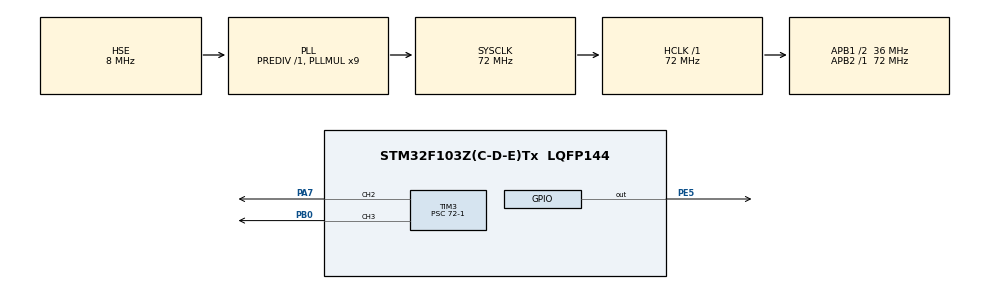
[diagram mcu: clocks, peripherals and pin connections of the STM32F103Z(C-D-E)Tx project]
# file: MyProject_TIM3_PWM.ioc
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Mcu.Family=STM32F1
Mcu.Name=STM32F103Z(C-D-E)Tx
Mcu.Package=LQFP144
NVIC.PriorityGroup=NVIC_PRIORITYGROUP_4
NVIC.TIM3_IRQn=true\:0\:0\:false\:false\:true\:true\:true
OSC_IN.Mode=HSE-External-Oscillator
OSC_IN.Signal=RCC_OSC_IN
OSC_OUT.Mode=HSE-External-Oscillator
OSC_OUT.Signal=RCC_OSC_OUT
PA7.Signal=S_TIM3_CH2
PB0.GPIO_Speed=GPIO_SPEED_FREQ_LOW
PB0.Signal=S_TIM3_CH3
PE5.Signal=GPIO_Output
ProjectManager.HeapSize=0x200
ProjectManager.StackSize=0x400
ProjectManager.TargetToolchain=MDK-ARM V5
RCC.AHBFreq_Value=72000000
RCC.APB1CLKDivider=RCC_HCLK_DIV2
RCC.APB1Freq_Value=36000000
RCC.APB1TimFreq_Value=72000000
RCC.APB2Freq_Value=72000000
RCC.APB2TimFreq_Value=72000000
RCC.HCLKFreq_Value=72000000
RCC.PLLMUL=RCC_PLL_MUL9
RCC.PLLSourceVirtual=RCC_PLLSOURCE_HSE
RCC.SYSCLKFreq_VALUE=72000000
RCC.SYSCLKSource=RCC_SYSCLKSOURCE_PLLCLK
RCC.USBFreq_Value=72000000
SH.S_TIM3_CH2.0=TIM3_CH2,PWM Generation2 CH2
SH.S_TIM3_CH3.0=TIM3_CH3,PWM Generation3 CH3
TIM3.AutoReloadPreload=TIM_AUTORELOAD_PRELOAD_ENABLE
TIM3.Channel-PWM\ Generation2\ CH2=TIM_CHANNEL_2
TIM3.Channel-PWM\ Generation3\ CH3=TIM_CHANNEL_3
TIM3.OCPolarity_3=TIM_OCPOLARITY_LOW
TIM3.Period=500-1
TIM3.Prescaler=72-1
VP_SYS_VS_ND.Mode=No_Debug
VP_TIM3_VS_ClockSourceINT.Mode=Internal
board=custom

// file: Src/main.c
/* USER CODE BEGIN Header */
/**
  ******************************************************************************
  * @file           : main.c
  * @brief          : Main program body
  ******************************************************************************
  * @attention
  *
  * <h2><center>&copy; Copyright (c) 2019 STMicroelectronics.
  * All rights reserved.</center></h2>
  *
  * This software component is licensed by ST under BSD 3-Clause license,
  * the "License"; You may not use this file except in compliance with the
  * License. You may obtain a copy of the License at:
  *                        opensource.org/licenses/BSD-3-Clause
  *
  ******************************************************************************
  */
/* USER CODE END Header */

#include "main.h"
#include "tim.h"
#include "gpio.h"

/* USER CODE BEGIN PV */
//uint8_t indexWave[] = {1,1,2,2,3,4,6,8,10,14,19,25,33,44,59,80,107,143,191,255,
//                       255,191,143,107,80,59,44,33,25,19,14,10,8,6,4,3,2,2,1,1};

/* USER CODE END PV */

void SystemClock_Config(void);

int main(void)
{
  /* USER CODE BEGIN 1 */
uint16_t pwm_Val = 0;
uint8_t pwd = 1;
//uint8_t dir = 1;
  /* USER CODE END 1 */

  /* MCU Configuration--------------------------------------------------------*/

  /* Reset of all peripherals, Initializes the Flash interface and the Systick. */
  HAL_Init();

  /* Configure the system clock */
  SystemClock_Config();

  /* Initialize all configured peripherals */
  MX_GPIO_Init();
  MX_TIM3_Init();
  /* USER CODE BEGIN 2 */
//  HAL_TIM_Base_Start_IT(&htim3);
  HAL_TIM_PWM_Start(&htim3,TIM_CHANNEL_3);
  /* USER CODE END 2 */

  /* Infinite loop */
  while (1)
  {

    /* USER CODE BEGIN 3 */
//     while(pwmVal < 500)
//     {
//        pwmVal++;
//
//        __HAL_TIM_SET_COMPARE(&htim3,TIM_CHANNEL_3,pwmVal);
//        HAL_Delay(1);
//     }
//     while(pwmVal)
//     {
//        pwmVal--;
//        __HAL_TIM_SET_COMPARE(&htim3,TIM_CHANNEL_3,pwmVal);
//         HAL_Delay(1);
//     }
//     HAL_Delay(200);

//      HAL_Delay(1000);
//		if(pwd)pwm_Val++;
//
//		else pwm_Val--;
//
// 		if(pwm_Val>500) pwd =0;
//
//		if(pwm_Val==0) pwd =1;

      HAL_Delay(200);

      if(pwd == 0)
      {
        pwm_Val ++;
          if(pwm_Val >=500)
          {
            pwd = 1;
          }
      }
      else
      {
        pwm_Val --;
          if(pwm_Val <= 10)
          {
            pwd= 0;
          }
      }
      __HAL_TIM_SET_COMPARE(&htim3,TIM_CHANNEL_3,pwm_Val);
  }
  /* USER CODE END 3 */
}

void SystemClock_Config(void)
{
  RCC_OscInitTypeDef RCC_OscInitStruct = {0};
  RCC_ClkInitTypeDef RCC_ClkInitStruct = {0};

  /** Initializes the CPU, AHB and APB busses clocks
  */
  RCC_OscInitStruct.OscillatorType = RCC_OSCILLATORTYPE_HSE;
  RCC_OscInitStruct.HSEState = RCC_HSE_ON;
  RCC_OscInitStruct.HSEPredivValue = RCC_HSE_PREDIV_DIV1;
  RCC_OscInitStruct.HSIState = RCC_HSI_ON;
  RCC_OscInitStruct.PLL.PLLState = RCC_PLL_ON;
  RCC_OscInitStruct.PLL.PLLSource = RCC_PLLSOURCE_HSE;
  RCC_OscInitStruct.PLL.PLLMUL = RCC_PLL_MUL9;
  if (HAL_RCC_OscConfig(&RCC_OscInitStruct) != HAL_OK)
  {
    Error_Handler();
  }
  /** Initializes the CPU, AHB and APB busses clocks
  */
  RCC_ClkInitStruct.ClockType = RCC_CLOCKTYPE_HCLK|RCC_CLOCKTYPE_SYSCLK
                              |RCC_CLOCKTYPE_PCLK1|RCC_CLOCKTYPE_PCLK2;
  RCC_ClkInitStruct.SYSCLKSource = RCC_SYSCLKSOURCE_PLLCLK;
  RCC_ClkInitStruct.AHBCLKDivider = RCC_SYSCLK_DIV1;
  RCC_ClkInitStruct.APB1CLKDivider = RCC_HCLK_DIV2;
  RCC_ClkInitStruct.APB2CLKDivider = RCC_HCLK_DIV1;

  if (HAL_RCC_ClockConfig(&RCC_ClkInitStruct, FLASH_LATENCY_2) != HAL_OK)
  {
    Error_Handler();
  }
}

/* USER CODE BEGIN 4 */
//void HAL_TIM_PeriodElapsedCallback(TIM_HandleTypeDef *htim)
//{
//  static uint8_t pwm_index = 1;			/* 用于PWM查表 */
//	static uint8_t period_cnt = 0;		/* 用于计算周期数 */

//  period_cnt++;
//  /* 若输出的周期数大于20，输出下一种脉冲宽的PWM波 */
//  if(period_cnt >= 20)
//  {
//    /* 根据PWM表修改定时器的比较寄存器值 */
//    __HAL_TIM_SetCompare(&htim3,TIM_CHANNEL_3,indexWave[pwm_index]);
//
//    /* 标志PWM表的下一个元素 */
//    pwm_index++;
//    /* 若PWM脉冲表已经输出完成一遍，重置PWM查表标志 */
//    if( pwm_index >=  40)
//    {
//      pwm_index=0;
//    }
//    /* 重置周期计数标志 */
//    period_cnt=0;
//  }
//}

/* USER CODE END 4 */

void Error_Handler(void)
{
}

/************************ (C) COPYRIGHT STMicroelectronics *****END OF FILE****/
